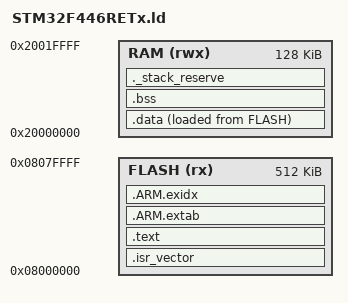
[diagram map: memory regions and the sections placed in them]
/* STM32F446RE: 512 KB flash, 128 KB SRAM */
ENTRY(Reset_Handler)

MEMORY
{
  FLASH (rx)  : ORIGIN = 0x08000000, LENGTH = 512K
  RAM   (rwx) : ORIGIN = 0x20000000, LENGTH = 128K
}

_estack = ORIGIN(RAM) + LENGTH(RAM);
_min_stack = 0x1000;

SECTIONS
{
  .isr_vector : { KEEP(*(.isr_vector)) } > FLASH

  .text :
  {
    *(.text*)
    *(.rodata*)
    KEEP(*(.init))
    KEEP(*(.fini))
    . = ALIGN(4);
  } > FLASH

  .ARM.extab : { *(.ARM.extab*) } > FLASH
  .ARM.exidx : { *(.ARM.exidx*) } > FLASH

  _sidata = LOADADDR(.data);
  .data :
  {
    . = ALIGN(4);
    _sdata = .;
    *(.data*)
    . = ALIGN(4);
    _edata = .;
  } > RAM AT > FLASH

  .bss (NOLOAD) :
  {
    . = ALIGN(4);
    _sbss = .;
    *(.bss*)
    *(COMMON)
    . = ALIGN(4);
    _ebss = .;
  } > RAM

  PROVIDE(end = _ebss);

  /* Fails the link if static data leaves less than _min_stack for the stack. */
  ._stack_reserve (NOLOAD) :
  {
    . = ALIGN(8);
    . = . + _min_stack;
  } > RAM
}
